# ADSP-2183xW_HPC register map
Vendor: Analog Devices; Series: ADSP-2183xW_HPC; File version: 3.0.3.517
CPU: 
Registers are 32-bit, read-write, reset 0x0 unless marked. A register's access mark holds for its fields unless they carry their own. Offsets are from the block's base; [hi:lo] are bit positions; {n}, {i} and the like mark numbered series; 'fields as' and 'values as' point back to an identical list.

## IIR0 — The IIR filter accelerator
Base 0x310C4000
Same registers: IIR1 0x310C0000
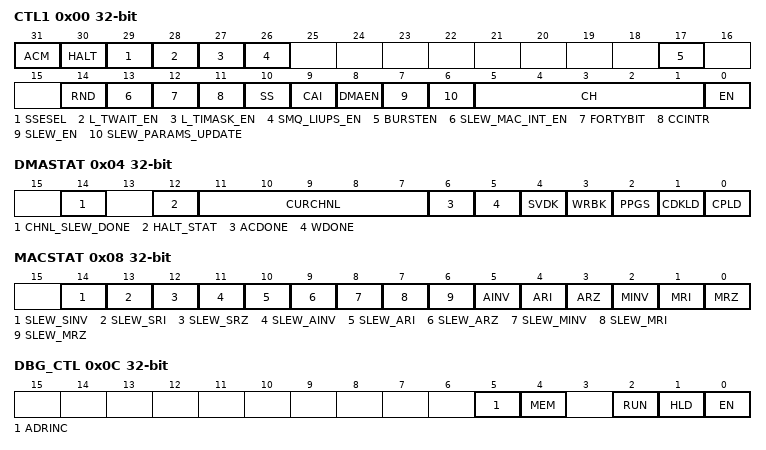
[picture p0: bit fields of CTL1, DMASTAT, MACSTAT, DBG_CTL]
0x00 CTL1 — Global Control Register
  [31] ACM — Auto Configuration Mode
    0=LEGACY (Legacy Mode); 1=AUTOCONFIG (Auto Configuration Mode)
  [30] HALT — Pause accelerator
  [29] SSESEL — Write Back Interrupt Select
  [28] L_TWAIT_EN — Enable TWAIT Feature in Legacy Mode
  [27] L_TIMASK_EN — Enable Trigger and Interrupt Masking in Legacy Mode
  [26] SMQ_LIUPS_EN — Legacy I/P and O/P Index Update Scheme in SMART_Q Mode
  [17] BURSTEN — Burst Mode Enable
  [14] RND — Rounding Mode
  [13] SLEW_MAC_INT_EN range 0x00000000..0x00000001 — Slew Interrupt Enable
  [12] FORTYBIT — 40-Bit Floating-Point Boundary Select
  [11] CCINTR — Channel Complete Interrupt
  [10] SS range 0x00000000..0x00000001 — Save Biquad State
  [9] CAI — Channel Auto Iterate
  [8] DMAEN — DMA Enable
  [7] SLEW_EN — Slewing Enable
  [6] SLEW_PARAMS_UPDATE range 0x00000000..0x00000001 — Slewing Parameters
  [5:1] CH range 0x00000000..0x0000001F — Number of Channels
  [0] EN — IIR Enable
0x04 DMASTAT — DMA Status Register
  [14] CHNL_SLEW_DONE ro — Channel Slew Done
  [12] HALT_STAT ro — Accelerator HALT status
  [11:7] CURCHNL ro — Current Channel
  [6] ACDONE ro — All Channels Done
  [5] WDONE ro — Current Channel Done
  [4] SVDK ro — Save Updated Dk State
  [3] WRBK ro — Write Back
  [2] PPGS ro — MAC Processing in Progress
  [1] CDKLD ro — Coefficient and Dk Loading
  [0] CPLD ro — Chain Pointer Loading Status
0x08 MACSTAT — MAC Status Register
  [14] SLEW_SINV ro — Subtraction Invalid
  [13] SLEW_SRI ro — Subtractor Result Infinity
  [12] SLEW_SRZ ro — Subtractor Result Zero
  [11] SLEW_AINV ro — Addition Invalid
  [10] SLEW_ARI ro — Adder Result Infinity
  [9] SLEW_ARZ ro — Adder Result Zero
  [8] SLEW_MINV ro — Multiply Invalid
  [7] SLEW_MRI ro — Multiplier Result Infinity
  [6] SLEW_MRZ ro — Multiplier Result Zero
  [5] AINV ro — Addition Invalid
  [4] ARI ro — Adder Result Infinity
  [3] ARZ ro — Adder Result Zero
  [2] MINV ro — Multiply Invalid
  [1] MRI ro — Multiplier Result Infinity
  [0] MRZ ro — Multiplier Result Zero
0x0C DBG_CTL — IIR Debug Control Register
  [5] ADRINC range 0x00000000..0x00000001 — Address Auto Increment
  [4] MEM range 0x00000000..0x00000001 — Local Memory Access
  [2] RUN range 0x00000000..0x00000001 — Release the MAC
  [1] HLD — Hold or Single Step
  [0] EN — Debug Mode Enable
0x10 DBG_ADDR — IIR Debug Address Register
  [10:0] VALUE range 0x00000000..0x000007FF — Debug Address, Coefficient Memory Select
0x14 DBG_WRDAT_LO — IIR Debug Write Data Low Register
  [31:0] VALUE range 0x00000000..0xFFFFFFFF — Debug Write Data Lower 32 Bits
0x18 DBG_WRDAT_HI — IIR Debug Write Data High Register
  [7:0] VALUE range 0x00000000..0x000000FF — Debug Write Data Highest 8 Bits
0x1C DBG_RDDAT_LO — IIR Debug Read Data Low Register
  [31:0] VALUE ro — Debug Read Data Lower 32 Bits
0x20 DBG_RDDAT_HI — IIR Debug Read Data High Register
  [7:0] VALUE ro — Debug Read Data Highest 8 Bits
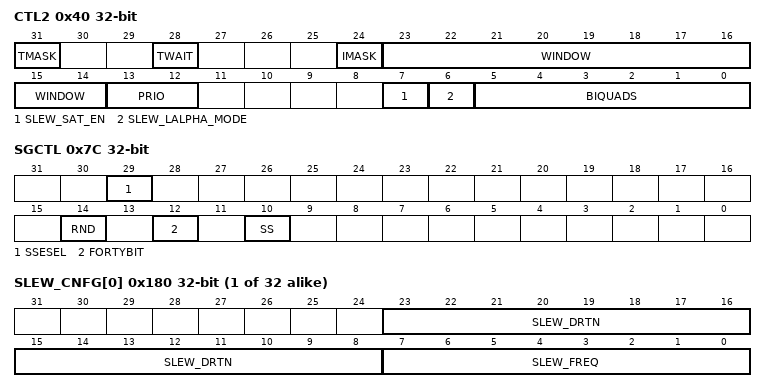
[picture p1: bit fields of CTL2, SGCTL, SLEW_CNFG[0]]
0x40 CTL2 — Channel Control Register
  [31] TMASK — Trigger mask bit
    0=TMASK_ENA (Enable); 1=TMASK_DIS (Mask)
  [28] TWAIT — Wait for trigger
    0=TWAIT_DIS (Disable wait for the trigger for the channel); 1=TWAIT_ENA (Enable wait for external trigger input assertion for the channel)
  [24] IMASK — Interrupt Mask
    0=IMASK_ENA (Enable); 1=IMASK_DIS (Mask)
  [23:14] WINDOW range 0x00000000..0x000003FF — Window Size Parameter
  [13:12] PRIO — Priority Level
    0=LEVEL0 (Level 0 (lowest)); 1=LEVEL1; 2=LEVEL2; 3=LEVEL3 (Level 3 (highest))
  [7] SLEW_SAT_EN range 0x00000000..0x00000001 — Control bit to choose the way slewing saturates
  [6] SLEW_LALPHA_MODE — Alpha Mode
  [5:0] BIQUADS range 0x00000000..0x0000003F — Number of Biquads
0x44 INIDX — Input Data Index Register
  [29:0] VALUE range 0x00000000..0x3FFFFFFF — Input Data Buffer Index
0x48 INMOD — Input Data Index Modifier Register
  [15:0] VALUE range 0x00000000..0x0000FFFF — 16-bit Input Data Buffer Index Modifier
0x4C INLEN — Input Data Buffer Length Register
  [15:0] VALUE range 0x00000000..0x0000FFFF — Input Data Buffer Length
0x50 INBASE — Input Buffer Base Register
  [29:0] VALUE range 0x00000000..0x3FFFFFFF — Input Data Buffer Base
0x54 OUTIDX — Output Data Buffer Index Register
  [29:0] VALUE range 0x00000000..0x3FFFFFFF — Output Data Buffer Index
0x58 OUTMOD — IIR Output Data Index Modifier Register
  fields as INMOD
0x5C OUTLEN — IIR Output Data Buffer Length Register
  [15:0] VALUE range 0x00000000..0x0000FFFF — 16-bit Output Data Buffer Length
0x60 OUTBASE — Output Buffer Base Register
  [29:0] VALUE range 0x00000000..0x3FFFFFFF — Output Buffer Base
0x64 COEFIDX — Coefficient Buffer Index Register
  [29:0] VALUE range 0x00000000..0x3FFFFFFF — Coefficient Buffer Index
0x68 COEFMOD — Coefficient Index Modifier Register
  [15:0] VALUE range 0x00000000..0x0000FFFF — Coefficient Modifier
0x6C COEFLEN — Coefficient Buffer Length Register
  [15:0] VALUE range 0x00000000..0x0000FFFF — Coefficient Length
0x70 CHNPTR — Chain Pointer Register
  [29:0] VALUE range 0x00000000..0x3FFFFFFF — IIR Chain Pointer Address
0x74 SCTL1 — Software Control Register1
  [31:0] VALUE range 0x00000000..0xFFFFFFFF — Software Control Register 1
0x78 SCTL2 — Software Control Register2
  [31:0] VALUE range 0x00000000..0xFFFFFFFF
0x7C SGCTL — Secondary Global Control Register
  [29] SSESEL range 0x00000000..0x00000001 — Select Between Write Back or Save State Completion Interrupt
  [14] RND — Rounding Mode Select
  [12] FORTYBIT — 40-Bit Floating-Point Format Select
  [10] SS range 0x00000000..0x00000001 — Save Biquad State
{0x100+4i} ALPHA[{i}] (i=0..31) — Channel n Alpha
  [31:0] VAL range 0x00000000..0xFFFFFFFF — Alpha Value
{0x180+4i} SLEW_CNFG[{i}] (i=0..31) — Channel 0 Slewing Duration and Frequency
  [23:8] SLEW_DRTN range 0x00000000..0x0000FFFF — Slewing Duration
  [7:0] SLEW_FREQ range 0x00000000..0x000000FF — Slewing Frequency

## IIR2 — The IIR filter accelerator
Base 0x310C1000
Same registers: IIR3 0x310C2000
Registers as IIR0, without ALPHA[{n}] (n=0..31), SLEW_CNFG[{n}] (n=0..31); these are added or differ:
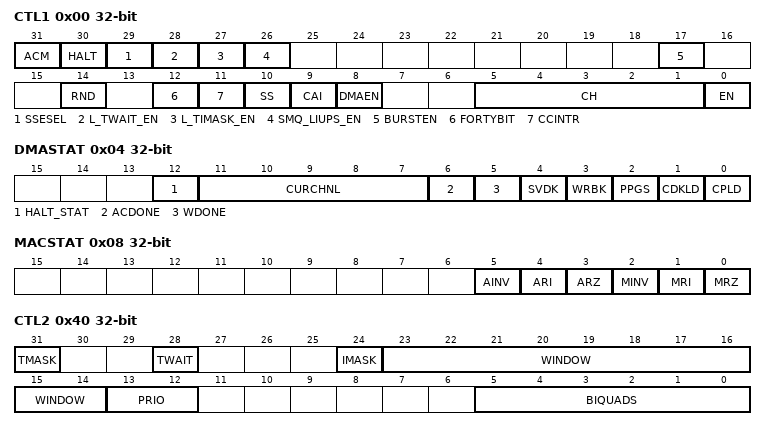
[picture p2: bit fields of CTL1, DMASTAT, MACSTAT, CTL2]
0x00 CTL1 — Global Control Register
  [31] ACM — Auto Configuration Mode
    0=LEGACY (Legacy Mode); 1=AUTOCONFIG (Auto Configuration Mode)
  [30] HALT — Pause accelerator
  [29] SSESEL — Write Back Interrupt Select
  [28] L_TWAIT_EN — Enable TWAIT Feature in Legacy Mode
  [27] L_TIMASK_EN — Enable Trigger and Interrupt Masking in Legacy Mode
  [26] SMQ_LIUPS_EN — Legacy I/P and O/P Index Update Scheme in SMART_Q Mode
  [17] BURSTEN — Burst Mode Enable
  [14] RND — Rounding Mode
  [12] FORTYBIT — 40-Bit Floating-Point Boundary Select
  [11] CCINTR — Channel Complete Interrupt
  [10] SS range 0x00000000..0x00000001 — Save Biquad State
  [9] CAI — Channel Auto Iterate
  [8] DMAEN — DMA Enable
  [5:1] CH range 0x00000000..0x0000001F — Number of Channels
  [0] EN — IIR Enable
0x04 DMASTAT — DMA Status Register
  [12] HALT_STAT ro — Accelerator HALT status
  [11:7] CURCHNL ro — Current Channel
  [6] ACDONE ro — All Channels Done
  [5] WDONE ro — Current Channel Done
  [4] SVDK ro — Save Updated Dk State
  [3] WRBK ro — Write Back
  [2] PPGS ro — MAC Processing in Progress
  [1] CDKLD ro — Coefficient and Dk Loading
  [0] CPLD ro — Chain Pointer Loading Status
0x08 MACSTAT — MAC Status Register
  [5] AINV ro — Addition Invalid
  [4] ARI ro — Adder Result Infinity
  [3] ARZ ro — Adder Result Zero
  [2] MINV ro — Multiply Invalid
  [1] MRI ro — Multiplier Result Infinity
  [0] MRZ ro — Multiplier Result Zero
0x40 CTL2 — Channel Control Register
  [31] TMASK — Trigger mask bit
    0=TMASK_ENA (Enable); 1=TMASK_DIS (Mask)
  [28] TWAIT — Wait for trigger
    0=TWAIT_DIS (Disable wait for the trigger for the channel); 1=TWAIT_ENA (Enable wait for external trigger input assertion for the channel)
  [24] IMASK — Interrupt Mask
    0=IMASK_ENA (Enable); 1=IMASK_DIS (Mask)
  [23:14] WINDOW range 0x00000000..0x000003FF — Window Size Parameter
  [13:12] PRIO — Priority Level
    0=LEVEL0 (Level 0 (lowest)); 1=LEVEL1; 2=LEVEL2; 3=LEVEL3 (Level 3 (highest))
  [5:0] BIQUADS range 0x00000000..0x0000003F — Number of Biquads
